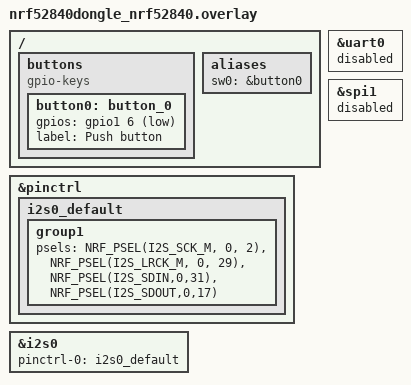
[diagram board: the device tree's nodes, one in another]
&pinctrl {
	i2s0_default: i2s0_default {
		group1 {
			psels = <NRF_PSEL(I2S_SCK_M, 0, 2)>,
				<NRF_PSEL(I2S_LRCK_M, 0, 29)>,
				<NRF_PSEL(I2S_SDIN,0,31)>,
				<NRF_PSEL(I2S_SDOUT,0,17)>;
		};
	};
};


&i2s0{
	status = "okay";
	pinctrl-0 = <&i2s0_default>;
	pinctrl-names = "default";
	};

//Below are disabled since 2 of those pins are configured for them
&uart0 {
	status="disabled";
};

&spi1{
	status="disabled";
};

//display
// &pinctrl {
//     i2c1_default: i2c1_default {
//         group1 {
//             psels = <NRF_PSEL(TWIM_SDA, 0, 22)>,
//                     <NRF_PSEL(TWIM_SCL, 0, 24)>;
//         };
//     };

//     i2c1_sleep: i2c1_sleep {
//         group1 {
//             psels = <NRF_PSEL(TWIM_SDA, 0, 22)>,
//                     <NRF_PSEL(TWIM_SCL, 0, 24)>;
//             low-power-enable;
//         };
//     };
// };

// &i2c1 {
//     status = "okay";
//     compatible = "nordic,nrf-twim";
//     pinctrl-0 = <&i2c1_default>;
//     pinctrl-1 = <&i2c1_sleep>;
//     pinctrl-names = "default", "sleep";

//     zephyr,concat-buf-size = <1040>;   /* >= 1 (control byte) + 1024 (128x64/8) */

//     ssd1306: ssd1306@3c {
//         compatible = "solomon,ssd1306";
//         reg = <0x3c>;
//         width = <128>;
//         height = <64>;
//         segment-offset = <0>;
//         page-offset = <0>;
//         display-offset = <0>;
//         multiplex-ratio = <63>;
//         segment-remap;
//         com-invdir;
//         prechargep = <0x22>;
//     };
// };


/ {
    buttons {
        compatible = "gpio-keys";

        button0: button_0 {
            gpios = <&gpio1 6 (GPIO_PULL_UP | GPIO_ACTIVE_LOW)>;
            label = "Push button";
        };
    };

    aliases {
        sw0 = &button0;
    };
};
